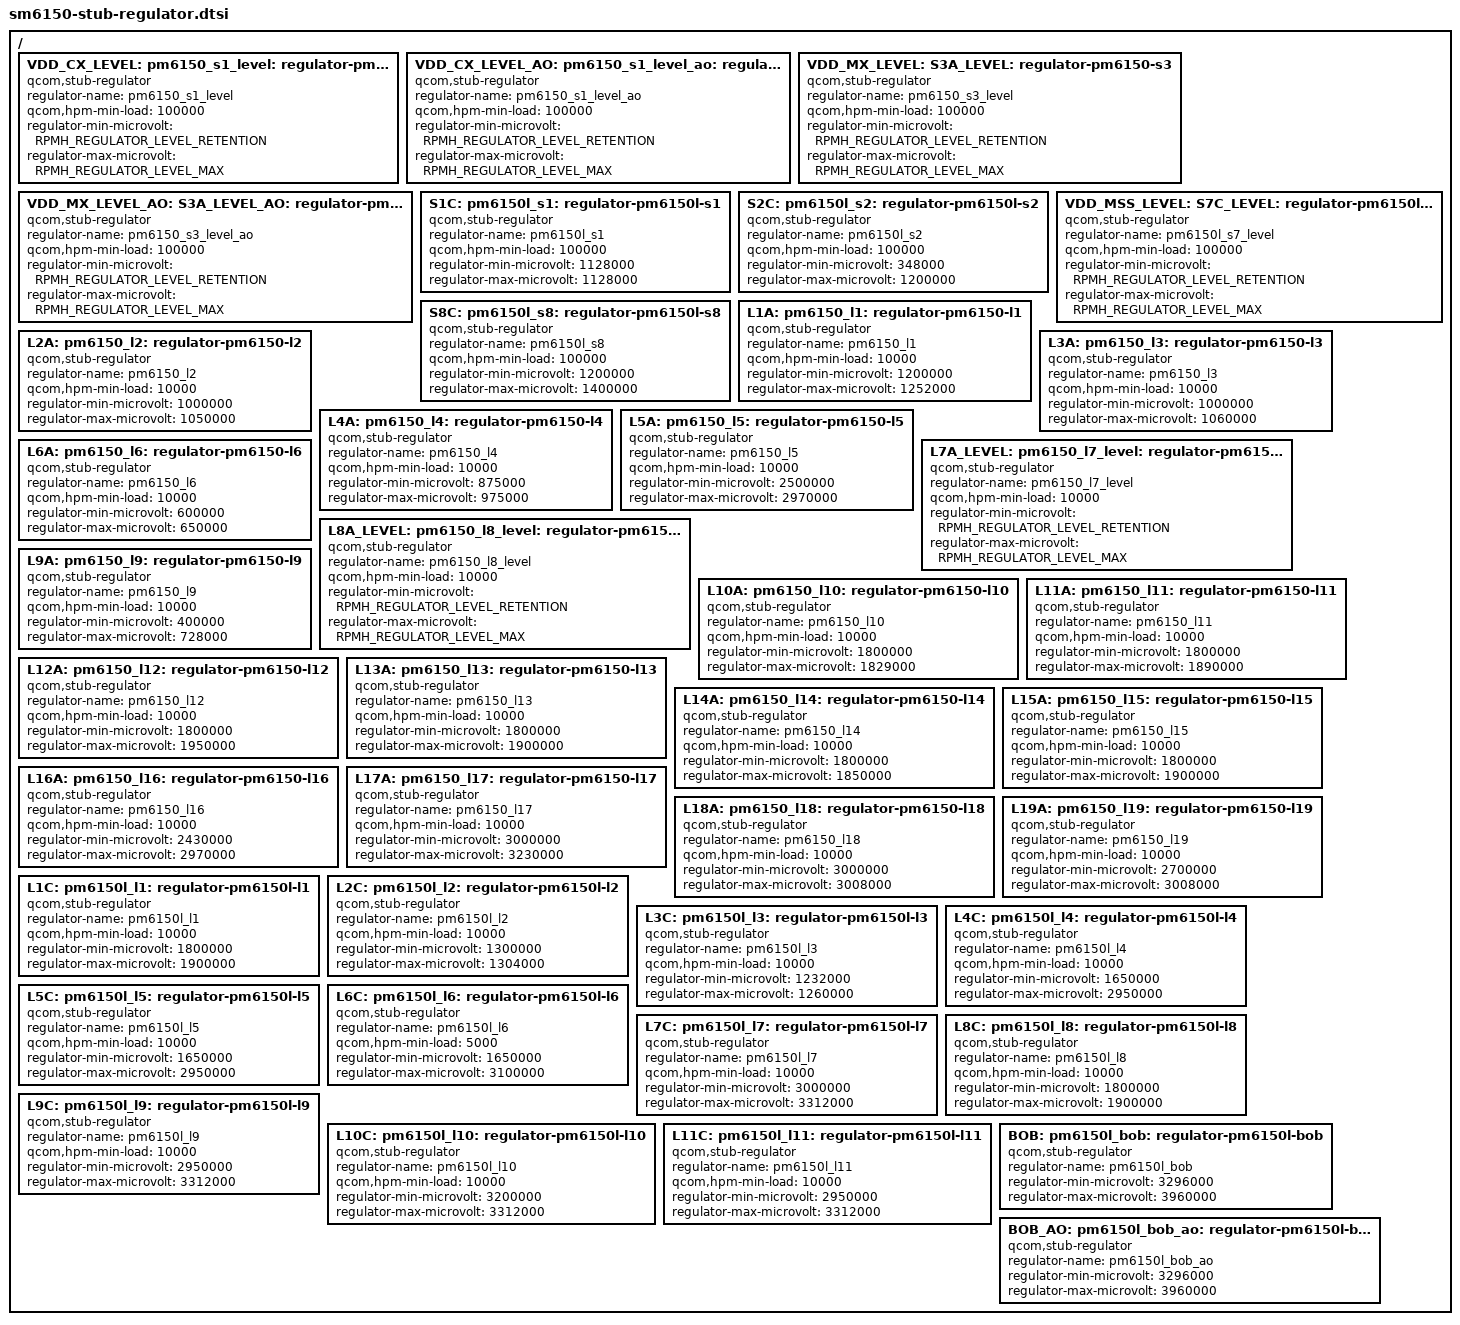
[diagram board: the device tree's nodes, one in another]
/* Copyright (c) 2018, The Linux Foundation. All rights reserved.
 *
 * This program is free software; you can redistribute it and/or modify
 * it under the terms of the GNU General Public License version 2 and
 * only version 2 as published by the Free Software Foundation.
 *
 * This program is distributed in the hope that it will be useful,
 * but WITHOUT ANY WARRANTY; without even the implied warranty of
 * MERCHANTABILITY or FITNESS FOR  PARTICULAR PURPOSE.  See the
 * GNU General Public License for more details.
 */

#include <dt-bindings/regulator/qcom,rpmh-regulator.h>

/* Stub regulators */

/ {
	/* pm6150 S1 - VDD_CX supply */
	VDD_CX_LEVEL:
	pm6150_s1_level: regulator-pm6150-s1 {
		compatible = "qcom,stub-regulator";
		regulator-name = "pm6150_s1_level";
		qcom,hpm-min-load = <100000>;
		regulator-min-microvolt = <RPMH_REGULATOR_LEVEL_RETENTION>;
		regulator-max-microvolt = <RPMH_REGULATOR_LEVEL_MAX>;
	};

	VDD_CX_LEVEL_AO:
	pm6150_s1_level_ao: regulator-pm6150-s1-level-ao {
		compatible = "qcom,stub-regulator";
		regulator-name = "pm6150_s1_level_ao";
		qcom,hpm-min-load = <100000>;
		regulator-min-microvolt = <RPMH_REGULATOR_LEVEL_RETENTION>;
		regulator-max-microvolt = <RPMH_REGULATOR_LEVEL_MAX>;
	};

	/* pm6150 S3 - VDD_MX supply */
	VDD_MX_LEVEL:
	S3A_LEVEL: pm6150_s3_level: regulator-pm6150-s3 {
		compatible = "qcom,stub-regulator";
		regulator-name = "pm6150_s3_level";
		qcom,hpm-min-load = <100000>;
		regulator-min-microvolt = <RPMH_REGULATOR_LEVEL_RETENTION>;
		regulator-max-microvolt = <RPMH_REGULATOR_LEVEL_MAX>;
	};

	VDD_MX_LEVEL_AO:
	S3A_LEVEL_AO: pm6150_s3_level_ao: regulator-pm6150-s3-level-ao {
		compatible = "qcom,stub-regulator";
		regulator-name = "pm6150_s3_level_ao";
		qcom,hpm-min-load = <100000>;
		regulator-min-microvolt = <RPMH_REGULATOR_LEVEL_RETENTION>;
		regulator-max-microvolt = <RPMH_REGULATOR_LEVEL_MAX>;
	};

	S1C: pm6150l_s1: regulator-pm6150l-s1 {
		compatible = "qcom,stub-regulator";
		regulator-name = "pm6150l_s1";
		qcom,hpm-min-load = <100000>;
		regulator-min-microvolt = <1128000>;
		regulator-max-microvolt = <1128000>;
	};

	S2C: pm6150l_s2: regulator-pm6150l-s2 {
		compatible = "qcom,stub-regulator";
		regulator-name = "pm6150l_s2";
		qcom,hpm-min-load = <100000>;
		regulator-min-microvolt = <348000>;
		regulator-max-microvolt = <1200000>;
	};

	/* pm6150l S7 - VDD_MSS supply */
	VDD_MSS_LEVEL:
	S7C_LEVEL: pm6150l_s7_level: regulator-pm6150l-s7 {
		compatible = "qcom,stub-regulator";
		regulator-name = "pm6150l_s7_level";
		qcom,hpm-min-load = <100000>;
		regulator-min-microvolt = <RPMH_REGULATOR_LEVEL_RETENTION>;
		regulator-max-microvolt = <RPMH_REGULATOR_LEVEL_MAX>;
	};

	S8C: pm6150l_s8: regulator-pm6150l-s8 {
		compatible = "qcom,stub-regulator";
		regulator-name = "pm6150l_s8";
		qcom,hpm-min-load = <100000>;
		regulator-min-microvolt = <1200000>;
		regulator-max-microvolt = <1400000>;
	};

	L1A: pm6150_l1: regulator-pm6150-l1 {
		compatible = "qcom,stub-regulator";
		regulator-name = "pm6150_l1";
		qcom,hpm-min-load = <10000>;
		regulator-min-microvolt = <1200000>;
		regulator-max-microvolt = <1252000>;
	};

	L2A: pm6150_l2: regulator-pm6150-l2 {
		compatible = "qcom,stub-regulator";
		regulator-name = "pm6150_l2";
		qcom,hpm-min-load = <10000>;
		regulator-min-microvolt = <1000000>;
		regulator-max-microvolt = <1050000>;
	};

	L3A: pm6150_l3: regulator-pm6150-l3 {
		compatible = "qcom,stub-regulator";
		regulator-name = "pm6150_l3";
		qcom,hpm-min-load = <10000>;
		regulator-min-microvolt = <1000000>;
		regulator-max-microvolt = <1060000>;
	};

	L4A: pm6150_l4: regulator-pm6150-l4 {
		compatible = "qcom,stub-regulator";
		regulator-name = "pm6150_l4";
		qcom,hpm-min-load = <10000>;
		regulator-min-microvolt = <875000>;
		regulator-max-microvolt = <975000>;
	};

	L5A: pm6150_l5: regulator-pm6150-l5 {
		compatible = "qcom,stub-regulator";
		regulator-name = "pm6150_l5";
		qcom,hpm-min-load = <10000>;
		regulator-min-microvolt = <2500000>;
		regulator-max-microvolt = <2970000>;
	};

	L6A: pm6150_l6: regulator-pm6150-l6 {
		compatible = "qcom,stub-regulator";
		regulator-name = "pm6150_l6";
		qcom,hpm-min-load = <10000>;
		regulator-min-microvolt = <600000>;
		regulator-max-microvolt = <650000>;
	};

	/* pm6150 L7 - LPI_MX supply */
	L7A_LEVEL: pm6150_l7_level: regulator-pm6150-l7 {
		compatible = "qcom,stub-regulator";
		regulator-name = "pm6150_l7_level";
		qcom,hpm-min-load = <10000>;
		regulator-min-microvolt = <RPMH_REGULATOR_LEVEL_RETENTION>;
		regulator-max-microvolt = <RPMH_REGULATOR_LEVEL_MAX>;
	};

	/* pm6150 L8 - LPI_CX supply */
	L8A_LEVEL: pm6150_l8_level: regulator-pm6150-l8 {
		compatible = "qcom,stub-regulator";
		regulator-name = "pm6150_l8_level";
		qcom,hpm-min-load = <10000>;
		regulator-min-microvolt = <RPMH_REGULATOR_LEVEL_RETENTION>;
		regulator-max-microvolt = <RPMH_REGULATOR_LEVEL_MAX>;
	};

	L9A: pm6150_l9: regulator-pm6150-l9 {
		compatible = "qcom,stub-regulator";
		regulator-name = "pm6150_l9";
		qcom,hpm-min-load = <10000>;
		regulator-min-microvolt = <400000>;
		regulator-max-microvolt = <728000>;
	};

	L10A: pm6150_l10: regulator-pm6150-l10 {
		compatible = "qcom,stub-regulator";
		regulator-name = "pm6150_l10";
		qcom,hpm-min-load = <10000>;
		regulator-min-microvolt = <1800000>;
		regulator-max-microvolt = <1829000>;
	};

	L11A: pm6150_l11: regulator-pm6150-l11 {
		compatible = "qcom,stub-regulator";
		regulator-name = "pm6150_l11";
		qcom,hpm-min-load = <10000>;
		regulator-min-microvolt = <1800000>;
		regulator-max-microvolt = <1890000>;
	};

	L12A: pm6150_l12: regulator-pm6150-l12 {
		compatible = "qcom,stub-regulator";
		regulator-name = "pm6150_l12";
		qcom,hpm-min-load = <10000>;
		regulator-min-microvolt = <1800000>;
		regulator-max-microvolt = <1950000>;
	};

	L13A: pm6150_l13: regulator-pm6150-l13 {
		compatible = "qcom,stub-regulator";
		regulator-name = "pm6150_l13";
		qcom,hpm-min-load = <10000>;
		regulator-min-microvolt = <1800000>;
		regulator-max-microvolt = <1900000>;
	};

	L14A: pm6150_l14: regulator-pm6150-l14 {
		compatible = "qcom,stub-regulator";
		regulator-name = "pm6150_l14";
		qcom,hpm-min-load = <10000>;
		regulator-min-microvolt = <1800000>;
		regulator-max-microvolt = <1850000>;
	};

	L15A: pm6150_l15: regulator-pm6150-l15 {
		compatible = "qcom,stub-regulator";
		regulator-name = "pm6150_l15";
		qcom,hpm-min-load = <10000>;
		regulator-min-microvolt = <1800000>;
		regulator-max-microvolt = <1900000>;
	};

	L16A: pm6150_l16: regulator-pm6150-l16 {
		compatible = "qcom,stub-regulator";
		regulator-name = "pm6150_l16";
		qcom,hpm-min-load = <10000>;
		regulator-min-microvolt = <2430000>;
		regulator-max-microvolt = <2970000>;
	};

	L17A: pm6150_l17: regulator-pm6150-l17 {
		compatible = "qcom,stub-regulator";
		regulator-name = "pm6150_l17";
		qcom,hpm-min-load = <10000>;
		regulator-min-microvolt = <3000000>;
		regulator-max-microvolt = <3230000>;
	};

	L18A: pm6150_l18: regulator-pm6150-l18 {
		compatible = "qcom,stub-regulator";
		regulator-name = "pm6150_l18";
		qcom,hpm-min-load = <10000>;
		regulator-min-microvolt = <3000000>;
		regulator-max-microvolt = <3008000>;
	};

	L19A: pm6150_l19: regulator-pm6150-l19 {
		compatible = "qcom,stub-regulator";
		regulator-name = "pm6150_l19";
		qcom,hpm-min-load = <10000>;
		regulator-min-microvolt = <2700000>;
		regulator-max-microvolt = <3008000>;
	};

	L1C: pm6150l_l1: regulator-pm6150l-l1 {
		compatible = "qcom,stub-regulator";
		regulator-name = "pm6150l_l1";
		qcom,hpm-min-load = <10000>;
		regulator-min-microvolt = <1800000>;
		regulator-max-microvolt = <1900000>;
	};

	L2C: pm6150l_l2: regulator-pm6150l-l2 {
		compatible = "qcom,stub-regulator";
		regulator-name = "pm6150l_l2";
		qcom,hpm-min-load = <10000>;
		regulator-min-microvolt = <1300000>;
		regulator-max-microvolt = <1304000>;
	};

	L3C: pm6150l_l3: regulator-pm6150l-l3 {
		compatible = "qcom,stub-regulator";
		regulator-name = "pm6150l_l3";
		qcom,hpm-min-load = <10000>;
		regulator-min-microvolt = <1232000>;
		regulator-max-microvolt = <1260000>;
	};

	L4C: pm6150l_l4: regulator-pm6150l-l4 {
		compatible = "qcom,stub-regulator";
		regulator-name = "pm6150l_l4";
		qcom,hpm-min-load = <10000>;
		regulator-min-microvolt = <1650000>;
		regulator-max-microvolt = <2950000>;
	};

	L5C: pm6150l_l5: regulator-pm6150l-l5 {
		compatible = "qcom,stub-regulator";
		regulator-name = "pm6150l_l5";
		qcom,hpm-min-load = <10000>;
		regulator-min-microvolt = <1650000>;
		regulator-max-microvolt = <2950000>;
	};

	L6C: pm6150l_l6: regulator-pm6150l-l6 {
		compatible = "qcom,stub-regulator";
		regulator-name = "pm6150l_l6";
		qcom,hpm-min-load = <5000>;
		regulator-min-microvolt = <1650000>;
		regulator-max-microvolt = <3100000>;
	};

	L7C: pm6150l_l7: regulator-pm6150l-l7 {
		compatible = "qcom,stub-regulator";
		regulator-name = "pm6150l_l7";
		qcom,hpm-min-load = <10000>;
		regulator-min-microvolt = <3000000>;
		regulator-max-microvolt = <3312000>;
	};

	L8C: pm6150l_l8: regulator-pm6150l-l8 {
		compatible = "qcom,stub-regulator";
		regulator-name = "pm6150l_l8";
		qcom,hpm-min-load = <10000>;
		regulator-min-microvolt = <1800000>;
		regulator-max-microvolt = <1900000>;
	};

	L9C: pm6150l_l9: regulator-pm6150l-l9 {
		compatible = "qcom,stub-regulator";
		regulator-name = "pm6150l_l9";
		qcom,hpm-min-load = <10000>;
		regulator-min-microvolt = <2950000>;
		regulator-max-microvolt = <3312000>;
	};

	L10C: pm6150l_l10: regulator-pm6150l-l10 {
		compatible = "qcom,stub-regulator";
		regulator-name = "pm6150l_l10";
		qcom,hpm-min-load = <10000>;
		regulator-min-microvolt = <3200000>;
		regulator-max-microvolt = <3312000>;
	};

	L11C: pm6150l_l11: regulator-pm6150l-l11 {
		compatible = "qcom,stub-regulator";
		regulator-name = "pm6150l_l11";
		qcom,hpm-min-load = <10000>;
		regulator-min-microvolt = <2950000>;
		regulator-max-microvolt = <3312000>;
	};

	BOB: pm6150l_bob: regulator-pm6150l-bob {
		compatible = "qcom,stub-regulator";
		regulator-name = "pm6150l_bob";
		regulator-min-microvolt = <3296000>;
		regulator-max-microvolt = <3960000>;
	};

	BOB_AO: pm6150l_bob_ao: regulator-pm6150l-bob-ao {
		compatible = "qcom,stub-regulator";
		regulator-name = "pm6150l_bob_ao";
		regulator-min-microvolt = <3296000>;
		regulator-max-microvolt = <3960000>;
	};
};
